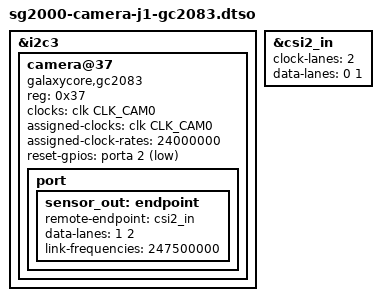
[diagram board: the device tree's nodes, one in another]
// SPDX-License-Identifier: (GPL-2.0 OR MIT)
/*
 * Milk-V CAM-GC2083 (GalaxyCore GC2083) on the Milk-V Duo S J1 connector.
 *
 * Enable with overlays=camera-j1-gc2083 in /boot/armbianEnv.txt.
 * Do not combine with a J2 camera overlay: both use CSI-2 MAC 0.
 *
 * J1 wiring, from the vendor's sensor_cfg_GC2083.ini for this board:
 *
 *   I2C3, sensor at 0x37
 *   CAM_MCLK0 (CLK_CAM0), 24 MHz requested, 23.76 MHz delivered
 *   CAM_RST0 = GPIOA2, active low
 *   MIPI RX lane 2 clock, lanes 0/1 data (lane_id = 2, 0, 1)
 *
 * The lane_id default in the vendor's GC2083 driver is 1, 0, 2. It is wrong
 * for this board, and the board's ini file replaces it at runtime.
 *
 * U-Boot sets the pinmux of the J1 pads. Do not add a pinctrl-0 to &i2c3:
 * the pull-ups on the board override the pull-down default of the pads.
 */
/dts-v1/;
/plugin/;

#include <dt-bindings/gpio/gpio.h>

#include "sg2000-camera.dtsi"

&i2c3 {
	#address-cells = <1>;
	#size-cells = <0>;

	camera@37 {
		compatible = "galaxycore,gc2083";
		reg = <0x37>;
		/* cam0pll is fractional: set the divider only, never the PLL */
		clocks = <&clk CLK_CAM0>;
		assigned-clocks = <&clk CLK_CAM0>;
		assigned-clock-rates = <24000000>;
		reset-gpios = <&porta 2 GPIO_ACTIVE_LOW>;

		port {
			sensor_out: endpoint {
				remote-endpoint = <&csi2_in>;
				data-lanes = <1 2>;
				link-frequencies = /bits/ 64 <247500000>;
			};
		};
	};
};

&csi2_in {
	clock-lanes = <2>;
	data-lanes = <0 1>;
};
